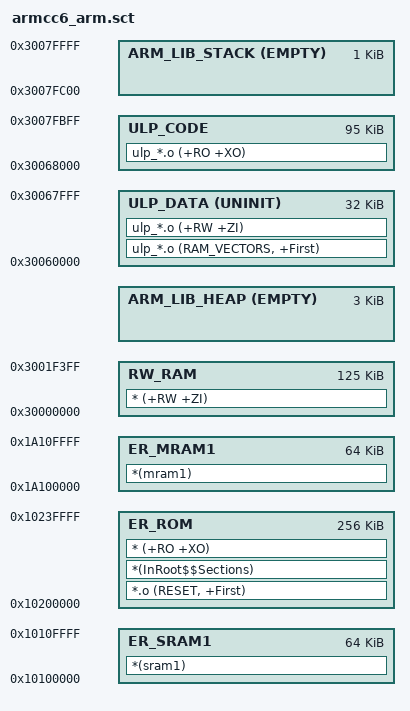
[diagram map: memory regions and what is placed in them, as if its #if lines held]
#! armclang -E --target=arm-arm-none-eabi -mcpu=cortex-m33 -xc
; command above MUST be in first line (no comment above!)

#if defined QSPI
  #define S_CODE_START   0x10200000
  #define S_CODE_SIZE    0x00040000
  
  #define S_DATA_START   0x30000000
  #define S_DATA_SIZE    0x00020000
#elif defined MRAM
  #define S_CODE_START   0x1A000000
  #define S_CODE_SIZE    0x00200000
  
  #define S_DATA_START   0x1A040000
  #define S_DATA_SIZE    0x00040000
#else
  #define S_CODE_START   0x10000000
  #define S_CODE_SIZE    0x00200000
  
  #define S_DATA_START   0x30000000
  #define S_DATA_SIZE    0x00020000
#endif


#define MRAM_BASE 0x1A000000
#define MRAM_SIZE 0x00200000

#define MRAM1_BASE 0x1A100000
#define MRAM1_SIZE 0x00010000
				  
#define SRAM1_BASE 0x10100000
#define SRAM1_SIZE 0x00010000
                   
#define QSPI1_BASE 0x10220000
#define QSPI1_SIZE 0x00010000

#define __ROM_BASE     S_CODE_START
#define __ROM_SIZE     S_CODE_SIZE

#define __RAM_BASE     S_DATA_START
#define __RAM_SIZE     S_DATA_SIZE

/*--------------------- Stack / Heap Configuration ---------------------------
; <h> Stack / Heap Configuration
;   <o0> Stack Size (in Bytes) <0x0-0xFFFFFFFF:8>
;   <o1> Heap Size (in Bytes) <0x0-0xFFFFFFFF:8>
; </h>
 *----------------------------------------------------------------------------*/
#define __STACK_SIZE       0x00000400
#define __HEAP_SIZE        0x00000C00

/*----------------------------------------------------------------------------
  SRAM3 = ULP Memory (not switched off during power down)
 *----------------------------------------------------------------------------*/
#define ULP_RAM_START         0x30060000
#define ULP_RAM_SIZE          0x00020000
#define ULP_RAM_DATA_START    (ULP_RAM_START)
#define ULP_RAM_DATA_SIZE     0x00008000
#define ULP_RAM_CODE_START    (ULP_RAM_DATA_START + ULP_RAM_DATA_SIZE)
#define ULP_RAM_CODE_SIZE     (ULP_RAM_SIZE - ULP_RAM_DATA_SIZE - __STACK_SIZE)

#define ULP_ER_RAM_START = 

;/*----------------------------------------------------------------------------
;  User Stack & Heap boundery definition
; *----------------------------------------------------------------------------*/
;#define __STACK_TOP        (__RAM_BASE + __RAM_SIZE)      /* starts at end of RAM */
;#define __HEAP_BASE        (AlignExpr(+0, 8))             /* starts after RW_RAM section, 8 byte aligned */
;//#define __HEAP_BASE        (__RAM_BASE + __RAM_SIZE - __STACK_SIZE - __HEAP_SIZE)

#define __STACK_TOP      (ULP_RAM_START + ULP_RAM_SIZE)   /* starts at end of ULP_RAM */
#define __HEAP_BASE      (AlignExpr(+0, 8))               /* starts after the section before (RW_RAM section), 8 byte aligned */



/*----------------------------------------------------------------------------
  Scatter File Definitions definition
 *----------------------------------------------------------------------------*/
;#define __RO_BASE         __ROM_BASE
;#define __RO_SIZE         __ROM_SIZE

;#define __RW_BASE        (__RAM_BASE        )
;#define __RW_SIZE        (__RAM_SIZE - __STACK_SIZE - __HEAP_SIZE)

#define __RO_BASE         S_CODE_START
#define __RO_SIZE         S_CODE_SIZE

#define __RW_BASE        S_DATA_START
#define __RW_SIZE        (S_DATA_SIZE - __HEAP_SIZE)


LR_ROM __RO_BASE __RO_SIZE  {                       ; load region size_region
  ER_ROM __RO_BASE __RO_SIZE  {                     ; load address = execution address
    *.o (RESET, +First)
    *(InRoot$$Sections)
//    *(Veneer$$CMSE)                               ; uncomment to locate SG veneers
    * (+RO +XO)
  }
  
  ER_MRAM1 MRAM1_BASE MRAM1_SIZE {
    *(mram1)    ; Place code to MRAM1
  }  
  
  ER_SRAM1 SRAM1_BASE SRAM1_SIZE {
    *(sram1)    ; Place code to SRAM1
  }  
 
;  RW_IRAM2 0x30070000 UNINIT 0x00001000  {  ; keep Event Recorder in the uninitialized RAM
;    EventRecorder.o (+ZI)
;  }
  
  ULP_DATA ULP_RAM_DATA_START UNINIT ULP_RAM_DATA_SIZE  {
    ulp_*.o (RAM_VECTORS, +First)
    ulp_*.o (+RW +ZI)
  }
  ULP_CODE ULP_RAM_CODE_START        ULP_RAM_CODE_SIZE  {
    ulp_*.o (+RO +XO)
  }
  
  RW_RAM __RW_BASE __RW_SIZE  {                     ; RW data
    * (+RW +ZI)
  }

  ARM_LIB_HEAP  __HEAP_BASE EMPTY  __HEAP_SIZE  { ; Reserve empty region for heap
  }

  ARM_LIB_STACK __STACK_TOP EMPTY -__STACK_SIZE { ; Reserve empty region for stack 
  }
}
